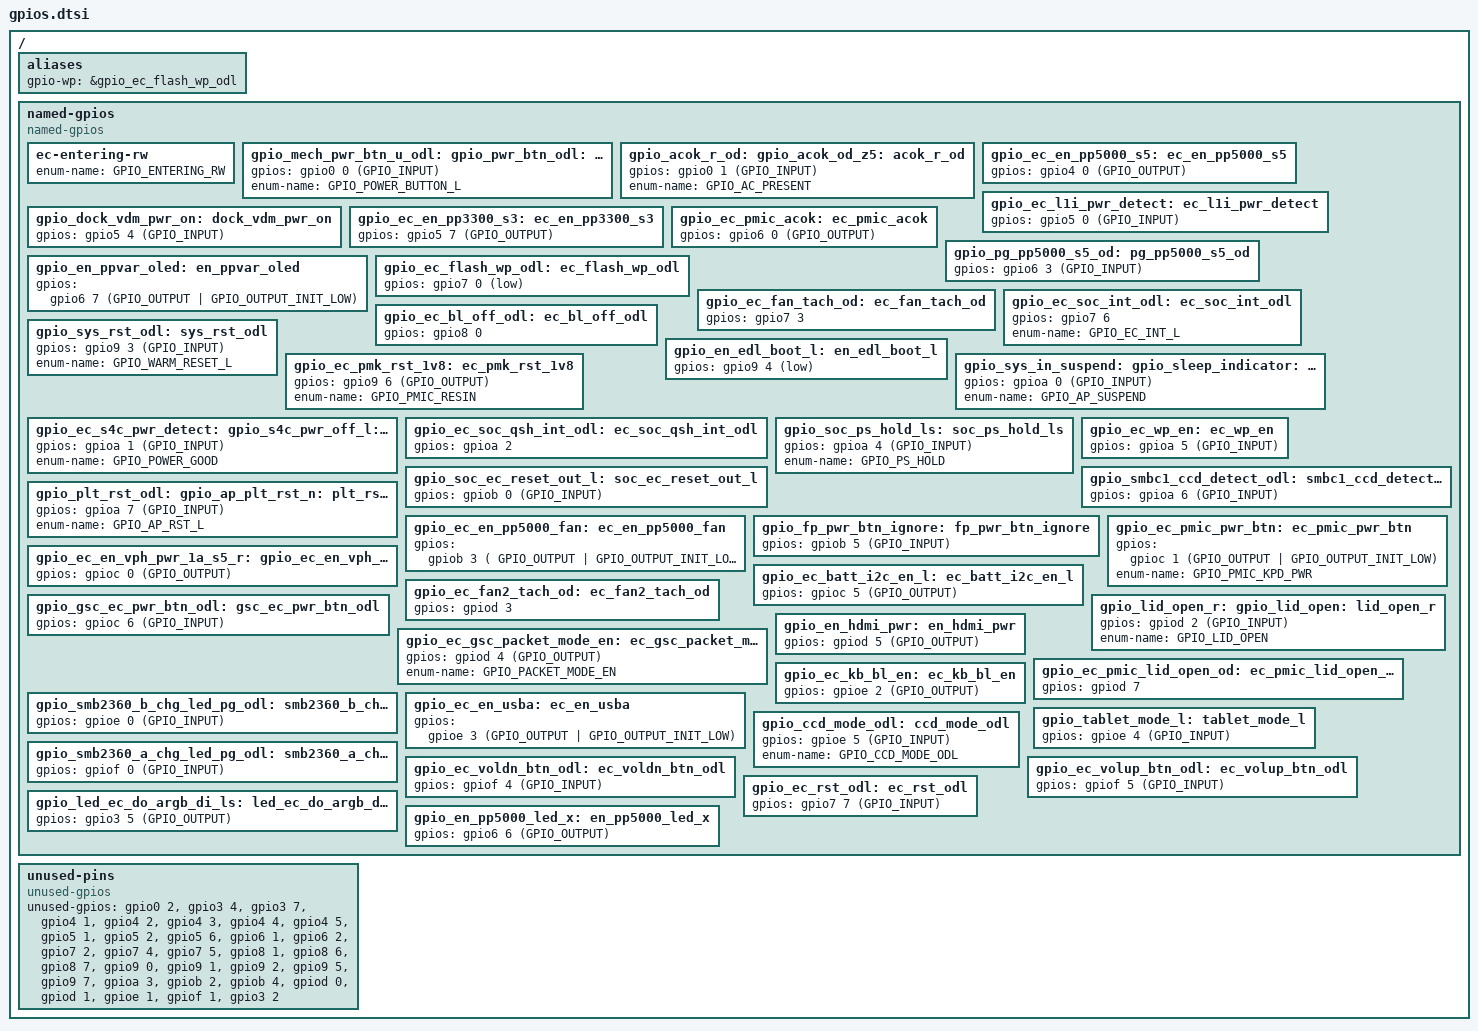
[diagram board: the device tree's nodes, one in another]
/* Copyright 2025 The ChromiumOS Authors
 * Use of this source code is governed by a BSD-style license that can be
 * found in the LICENSE file.
 */

/ {
	aliases {
		gpio-wp = &gpio_ec_flash_wp_odl;
	};

	named-gpios {
		compatible = "named-gpios";

		/* The legacy system code requires GPIO_ENTERING_RW symbol. */
		ec-entering-rw {
			enum-name = "GPIO_ENTERING_RW";
		};
		gpio_mech_pwr_btn_u_odl: mech_pwr_btn_u_odl {
			gpios = <&gpio0 0 (GPIO_INPUT)>;
			enum-name = "GPIO_POWER_BUTTON_L";
		};
		gpio_acok_r_od: acok_r_od {
			gpios = <&gpio0 1 (GPIO_INPUT)>;
			enum-name = "GPIO_AC_PRESENT";
		};
		gpio_ec_en_pp5000_s5: ec_en_pp5000_s5 {
			gpios = <&gpio4 0 (GPIO_OUTPUT)>;
		};
		gpio_ec_l1i_pwr_detect: ec_l1i_pwr_detect {
			gpios = <&gpio5 0 (GPIO_INPUT)>;
		};
		gpio_dock_vdm_pwr_on: dock_vdm_pwr_on {
			gpios = <&gpio5 4 (GPIO_INPUT)>;
		};
		gpio_ec_en_pp3300_s3: ec_en_pp3300_s3 {
			gpios = <&gpio5 7 (GPIO_OUTPUT)>;
		};
		gpio_ec_pmic_acok: ec_pmic_acok {
			gpios = <&gpio6 0 (GPIO_OUTPUT)>;
		};
		gpio_pg_pp5000_s5_od: pg_pp5000_s5_od {
			gpios = <&gpio6 3 (GPIO_INPUT)>;
		};
		gpio_en_ppvar_oled: en_ppvar_oled {
			gpios = <&gpio6 7 (GPIO_OUTPUT | GPIO_OUTPUT_INIT_LOW)>;
		};
		gpio_ec_flash_wp_odl: ec_flash_wp_odl {
			gpios = <&gpio7 0 (GPIO_INPUT | GPIO_ACTIVE_LOW)>;
		};
		gpio_ec_fan_tach_od: ec_fan_tach_od {
			gpios = <&gpio7 3 (GPIO_INPUT | GPIO_PULL_UP)>;
		};
		gpio_ec_soc_int_odl: ec_soc_int_odl {
			gpios = <&gpio7 6 (GPIO_OUTPUT | GPIO_OPEN_DRAIN)>;
			enum-name = "GPIO_EC_INT_L";
		};
		gpio_ec_bl_off_odl: ec_bl_off_odl {
			gpios = <&gpio8 0 (GPIO_OUTPUT | GPIO_OPEN_DRAIN)>;
		};
		gpio_sys_rst_odl: sys_rst_odl {
			gpios = <&gpio9 3 (GPIO_INPUT)>;
			enum-name = "GPIO_WARM_RESET_L";
		};
		gpio_en_edl_boot_l: en_edl_boot_l {
			gpios = <&gpio9 4 (GPIO_OUTPUT | GPIO_OPEN_DRAIN |
													GPIO_ACTIVE_LOW | GPIO_OUTPUT_INACTIVE)>;
		};
		gpio_ec_pmk_rst_1v8: ec_pmk_rst_1v8 {
			gpios = <&gpio9 6 (GPIO_OUTPUT)>;
			enum-name = "GPIO_PMIC_RESIN";
		};
		gpio_sys_in_suspend: sys_in_suspend {
			gpios = <&gpioa 0 (GPIO_INPUT)>;
			enum-name = "GPIO_AP_SUSPEND";
		};
		gpio_ec_s4c_pwr_detect: ec_s4c_pwr_detect {
			gpios = <&gpioa 1 (GPIO_INPUT)>;
			enum-name = "GPIO_POWER_GOOD";
		};
		gpio_ec_soc_qsh_int_odl: ec_soc_qsh_int_odl {
			gpios = <&gpioa 2 (GPIO_OUTPUT | GPIO_OPEN_DRAIN)>;
		};
		gpio_soc_ps_hold_ls: soc_ps_hold_ls {
			gpios = <&gpioa 4 (GPIO_INPUT)>;
			enum-name = "GPIO_PS_HOLD";
		};
		gpio_ec_wp_en: ec_wp_en {
			gpios = <&gpioa 5 (GPIO_INPUT)>;
		};
		gpio_smbc1_ccd_detect_odl: smbc1_ccd_detect_odl {
			gpios = <&gpioa 6 (GPIO_INPUT)>;
		};
		gpio_plt_rst_odl: plt_rst_odl {
			gpios = <&gpioa 7 (GPIO_INPUT)>;
			enum-name = "GPIO_AP_RST_L";
		};
		gpio_soc_ec_reset_out_l: soc_ec_reset_out_l {
			gpios = <&gpiob 0 (GPIO_INPUT)>;
		};
		gpio_ec_en_pp5000_fan: ec_en_pp5000_fan {
			gpios = <&gpiob 3 ( GPIO_OUTPUT | GPIO_OUTPUT_INIT_LOW)>;
		};
		gpio_fp_pwr_btn_ignore: fp_pwr_btn_ignore {
			gpios = <&gpiob 5 (GPIO_INPUT)>;
		};
		gpio_ec_en_vph_pwr_1a_s5_r: ec_en_vph_pwr_1a_s5_r {
			gpios = <&gpioc 0 (GPIO_OUTPUT)>;
		};
		gpio_ec_pmic_pwr_btn: ec_pmic_pwr_btn {
			gpios = <&gpioc 1 (GPIO_OUTPUT | GPIO_OUTPUT_INIT_LOW)>;
			enum-name = "GPIO_PMIC_KPD_PWR";
		};
		gpio_ec_batt_i2c_en_l: ec_batt_i2c_en_l {
			gpios = <&gpioc 5 (GPIO_OUTPUT)>;
		};
		gpio_gsc_ec_pwr_btn_odl: gsc_ec_pwr_btn_odl {
			gpios = <&gpioc 6 (GPIO_INPUT)>;
		};
		gpio_lid_open_r: lid_open_r {
			gpios = <&gpiod 2 (GPIO_INPUT)>;
			enum-name = "GPIO_LID_OPEN";
		};
		gpio_ec_fan2_tach_od: ec_fan2_tach_od {
			gpios = <&gpiod 3 (GPIO_INPUT | GPIO_PULL_UP)>;
		};
		gpio_ec_gsc_packet_mode_en: ec_gsc_packet_mode_en {
			gpios = <&gpiod 4 (GPIO_OUTPUT)>;
			enum-name = "GPIO_PACKET_MODE_EN";
		};
		gpio_en_hdmi_pwr: en_hdmi_pwr {
			gpios = <&gpiod 5 (GPIO_OUTPUT)>;
		};
		gpio_ec_pmic_lid_open_od: ec_pmic_lid_open_od {
			gpios = <&gpiod 7 (GPIO_OUTPUT | GPIO_OPEN_DRAIN)>;
		};
		gpio_smb2360_b_chg_led_pg_odl: smb2360_b_chg_led_pg_odl {
			gpios = <&gpioe 0 (GPIO_INPUT)>;
		};
		gpio_ec_kb_bl_en: ec_kb_bl_en {
			gpios = <&gpioe 2 (GPIO_OUTPUT)>;
		};
		gpio_ec_en_usba: ec_en_usba {
			gpios = <&gpioe 3 (GPIO_OUTPUT | GPIO_OUTPUT_INIT_LOW)>;
		};
		gpio_tablet_mode_l: tablet_mode_l {
			gpios = <&gpioe 4 (GPIO_INPUT)>;
		};
		gpio_ccd_mode_odl: ccd_mode_odl {
			gpios = <&gpioe 5 (GPIO_INPUT)>;
			enum-name = "GPIO_CCD_MODE_ODL";
		};
		gpio_smb2360_a_chg_led_pg_odl: smb2360_a_chg_led_pg_odl {
			gpios = <&gpiof 0 (GPIO_INPUT)>;
		};
		gpio_ec_voldn_btn_odl: ec_voldn_btn_odl {
			gpios = <&gpiof 4 (GPIO_INPUT)>;
		};
		gpio_ec_volup_btn_odl: ec_volup_btn_odl {
			gpios = <&gpiof 5 (GPIO_INPUT)>;
		};
		gpio_led_ec_do_argb_di_ls: led_ec_do_argb_di_ls {
			gpios = <&gpio3 5 (GPIO_OUTPUT)>;
		};
		gpio_en_pp5000_led_x: en_pp5000_led_x {
			gpios = <&gpio6 6 (GPIO_OUTPUT)>;
		};
		gpio_ec_rst_odl: ec_rst_odl {
			gpios = <&gpio7 7 (GPIO_INPUT)>;
		};
	};
	unused-pins {
		compatible = "unused-gpios";

		unused-gpios =
			<&gpio0 2 0>,
			<&gpio3 4 0>,
			<&gpio3 7 0>,
			<&gpio4 1 0>,
			<&gpio4 2 0>,
			<&gpio4 3 0>,
			<&gpio4 4 0>,
			<&gpio4 5 0>,
			<&gpio5 1 0>,
			<&gpio5 2 0>,
			<&gpio5 6 0>,
			<&gpio6 1 0>,
			<&gpio6 2 0>,
			<&gpio7 2 0>,
			<&gpio7 4 0>,
			<&gpio7 5 0>,
			<&gpio8 1 0>,
			<&gpio8 6 0>,
			<&gpio8 7 0>,
			<&gpio9 0 0>,
			<&gpio9 1 0>,
			<&gpio9 2 0>,
			<&gpio9 5 0>,
			<&gpio9 7 0>,
			<&gpioa 3 0>,
			<&gpiob 2 0>,
			<&gpiob 4 0>,
			<&gpiod 0 0>,
			<&gpiod 1 0>,
			<&gpioe 1 0>,
			<&gpiof 1 0>,
			<&gpio3 2 0>;
	};
};

/*
 * Aliases interrupt to common names
 */
gpio_acok_od_z5: &gpio_acok_r_od {};
gpio_lid_open: &gpio_lid_open_r {};
gpio_pwr_btn_odl: &gpio_mech_pwr_btn_u_odl {};
gpio_s4c_pwr_off_l: &gpio_ec_s4c_pwr_detect {};
gpio_ap_plt_rst_n: &gpio_plt_rst_odl {};
gpio_sleep_indicator: &gpio_sys_in_suspend {};
gpio_soc_ps_hold_ls: &gpio_soc_ps_hold_ls {};
gpio_sys_rst_odl: &gpio_sys_rst_odl {};

/*
 * Aliases switchcap to common names
 */
gpio_ec_en_vph_pwr_1a: &gpio_ec_en_vph_pwr_1a_s5_r {};
